# CH32L103 register map
Vendor: WCH Ltd.; File version: 1.3
Registers are 32-bit, read-write, reset 0x0 unless marked. A register's access mark holds for its fields unless they carry their own. Offsets are from the block's base; [hi:lo] are bit positions; {n}, {i} and the like mark numbered series; 'fields as' and 'values as' point back to an identical list.

## CAN — Controller area network
Base 0x40006400
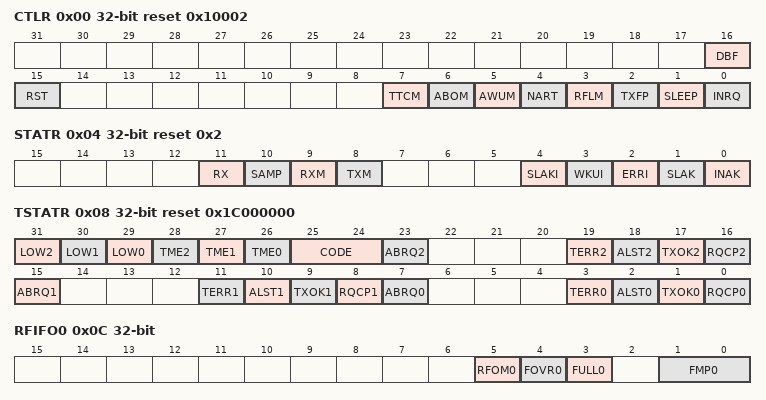
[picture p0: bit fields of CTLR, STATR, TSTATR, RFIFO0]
0x00 CTLR reset 0x10002 — CAN Master control register
  [16] DBF — Debug freeze
  [15] RST — Software master reset
  [7] TTCM — Time triggered communication mode
  [6] ABOM — Automatic bus-off management
  [5] AWUM — Automatic wakeup mode
  [4] NART — No automatic retransmission
  [3] RFLM — Receive FIFO locked mode
  [2] TXFP — Transmit FIFO priority
  [1] SLEEP — Sleep mode request bit
  [0] INRQ — Initialization request
0x04 STATR access per field reset 0x2 — CAN master status register
  [11] RX ro — Rx signal
  [10] SAMP ro — Last sample point
  [9] RXM ro — Receive mode
  [8] TXM ro — Transmit mode
  [4] SLAKI rw — Sleep acknowledge interrupt
  [3] WKUI rw — Wakeup interrupt
  [2] ERRI rw — Error interrupt
  [1] SLAK ro — Sleep acknowledge
  [0] INAK ro — Initialization acknowledge
0x08 TSTATR access per field reset 0x1C000000 — CAN transmit status register
  [31] LOW2 ro — Lowest priority flag for mailbox2
  [30] LOW1 ro — Lowest priority flag for mailbox1
  [29] LOW0 ro — Lowest priority flag for mailbox0
  [28] TME2 ro — Transmit mailbox 2 empty
  [27] TME1 ro — Transmit mailbox 1 empty
  [26] TME0 ro — Transmit mailbox 0 empty
  [25:24] CODE ro — Mailbox code
  [23] ABRQ2 rw — Abort request for mailbox 2
  [19] TERR2 rw — Transmission error of mailbox 2
  [18] ALST2 rw — Arbitration lost for mailbox 2
  [17] TXOK2 rw — Transmission OK of mailbox 2
  [16] RQCP2 rw — Request completed mailbox2
  [15] ABRQ1 rw — Abort request for mailbox 1
  [11] TERR1 rw — Transmission error of mailbox1
  [10] ALST1 rw — Arbitration lost for mailbox1
  [9] TXOK1 rw — Transmission OK of mailbox1
  [8] RQCP1 rw — Request completed mailbox1
  [7] ABRQ0 rw — Abort request for mailbox0
  [3] TERR0 rw — Transmission error of mailbox0
  [2] ALST0 rw — Arbitration lost for mailbox0
  [1] TXOK0 rw — Transmission OK of mailbox0
  [0] RQCP0 rw — Request completed mailbox0
0x0C RFIFO0 access per field — CAN receive FIFO 0 register
  [5] RFOM0 rw — Release FIFO 0 output mailbox
  [4] FOVR0 rw — FIFO 0 overrun
  [3] FULL0 rw — FIFO 0 full
  [1:0] FMP0 ro — FIFO 0 message pending
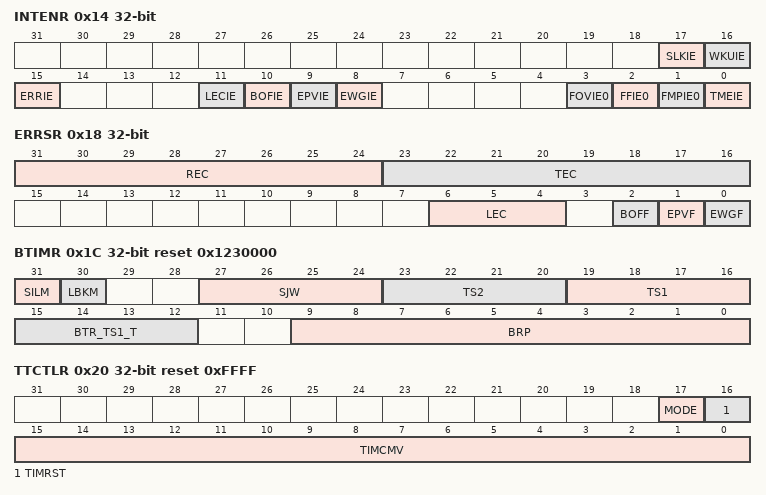
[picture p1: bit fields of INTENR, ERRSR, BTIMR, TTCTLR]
0x14 INTENR — CAN interrupt enable register
  [17] SLKIE — Sleep interrupt enable
  [16] WKUIE — Wakeup interrupt enable
  [15] ERRIE — Error interrupt enable
  [11] LECIE — Last error code interrupt enable
  [10] BOFIE — Bus-off interrupt enable
  [9] EPVIE — Error passive interrupt enable
  [8] EWGIE — Error warning interrupt enable
  [3] FOVIE0 — FIFO overrun interrupt enable
  [2] FFIE0 — FIFO full interrupt enable
  [1] FMPIE0 — FIFO message pending interrupt enable
  [0] TMEIE — Transmit mailbox empty interrupt enable
0x18 ERRSR access per field — CAN error status register
  [31:24] REC ro — Receive error counter
  [23:16] TEC ro — Least significant byte of the 9-bit transmit error counter
  [6:4] LEC rw — Last error code
  [2] BOFF ro — Bus-off flag
  [1] EPVF ro — Error passive flag
  [0] EWGF ro — Error warning flag
0x1C BTIMR reset 0x1230000 — CAN bit timing register
  [31] SILM — Silent mode (debug)
  [30] LBKM — Loop back mode (debug)
  [27:24] SJW — Resynchronization jump width
  [23:20] TS2 — Time segment 2
  [19:16] TS1 — Time segment 1
  [15:12] BTR_TS1_T — CLAS_LONG_TS1=0;TS1 is TS[3:0](4bit);CLAS_LONG_TS1=1,TS1 is TS[1:0]+BTR_TS1_T[15:12](6bit)
  [9:0] BRP — minimum time unit length setting value
0x20 TTCTLR reset 0xFFFF — CAN time trigger control register
  [17] MODE — Time-triggered mode selection
  [16] TIMRST wo — Internal counter reset control
  [15:0] TIMCMV — Internal counter count end value
0x24 TTCNT — CAN Time Trigger Count Value Register
  [15:0] TIMCNT — time-triggered count value
0x28 TERR_CNT — CAN offline recovery error counter
  [8:0] TX_ERR_CNT — Offline recovery error count values
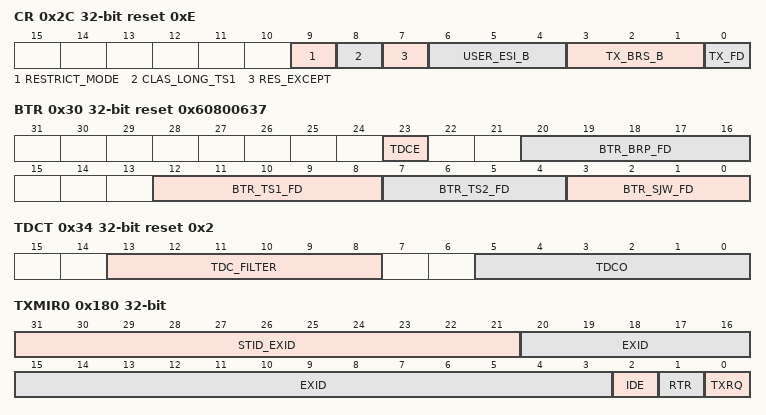
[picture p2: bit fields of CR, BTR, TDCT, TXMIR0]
0x2C CR reset 0xE — CANFD control register
  [9] RESTRICT_MODE — Mode enable
  [8] CLAS_LONG_TS1 — TS1 stage length selection
  [7] RES_EXCEPT — RES Bit exceptional enable
  [6:4] USER_ESI_B — ESI status
  [3:1] TX_BRS_B — Channel switchover enable
  [0] TX_FD — Send the FD frame enable bit
0x30 BTR reset 0x60800637 — CANFD Sequential register
  [23] TDCE — FD Frame sending delay compensation enable
  [20:16] BTR_BRP_FD — Minimum time length setting value
  [12:8] BTR_TS1_FD — Time range 1 set value
  [7:4] BTR_TS2_FD — Time range 2 set value
  [3:0] BTR_SJW_FD — Resynchronization width setting
0x34 TDCT reset 0x2 — CANFD Send delay compensation register
  [13:8] TDC_FILTER — Transmitter delay timing filtering
  [5:0] TDCO — Transmitter delay compensation offset
0x38 PSR ro — CANFD Send delay compensation value register
  [23:16] TDCV — FD Send delay compensation value
{0x3C+4i} DMA_T{i} (i=0..2) — CANFD DMA send mailbox {i} address register
  [14:0] DMA_ADDR_T{i} — Send buffer
0x48 DMA_R0 — CANFD DMA receives mailbox 0 address register
  [14:0] DMA_ADDR_R0 — Receive buffer
0x180 TXMIR0 — CAN TX mailbox identifier register
  [31:21] STID_EXID — Standard identifier
  [20:3] EXID — extended identifier
  [2] IDE — Identifier extension
  [1] RTR — Remote transmission request
  [0] TXRQ — Transmit mailbox request
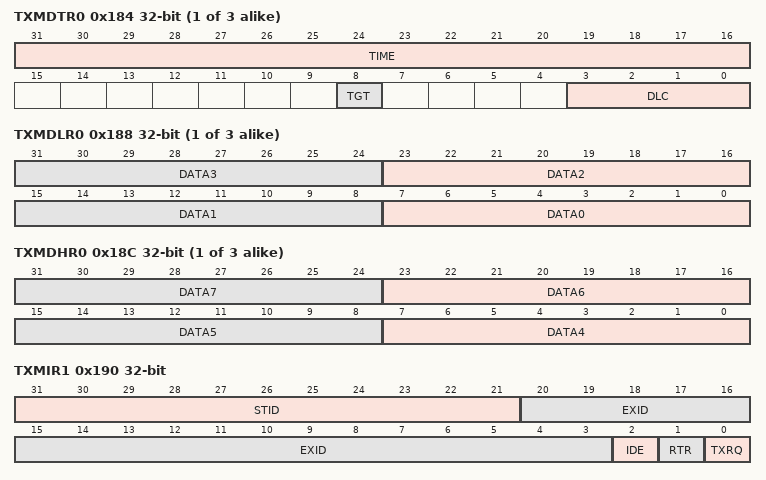
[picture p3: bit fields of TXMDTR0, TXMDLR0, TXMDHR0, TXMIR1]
{0x184+0x10*i} TXMDTR{i} (i=0..2) — CAN mailbox data length control and time stamp register
  [31:16] TIME — Message time stamp
  [8] TGT — Transmit global time
  [3:0] DLC — Data length code
{0x188+0x10*i} TXMDLR{i} (i=0..2) — CAN mailbox data low register
  [8n+7:8n] DATA{n} (n=0..3) — Data byte {n}
{0x18C+0x10*i} TXMDHR{i} (i=0..2) — CAN mailbox data high register
  [8n-25:8n-32] DATA{n} (n=4..7) — Data byte {n}
0x190 TXMIR1 — CAN TX mailbox identifier register
  [31:21] STID — Standard identifier
  [20:3] EXID — extended identifier
  [2] IDE — Identifier extension
  [1] RTR — Remote transmission request
  [0] TXRQ — Transmit mailbox request
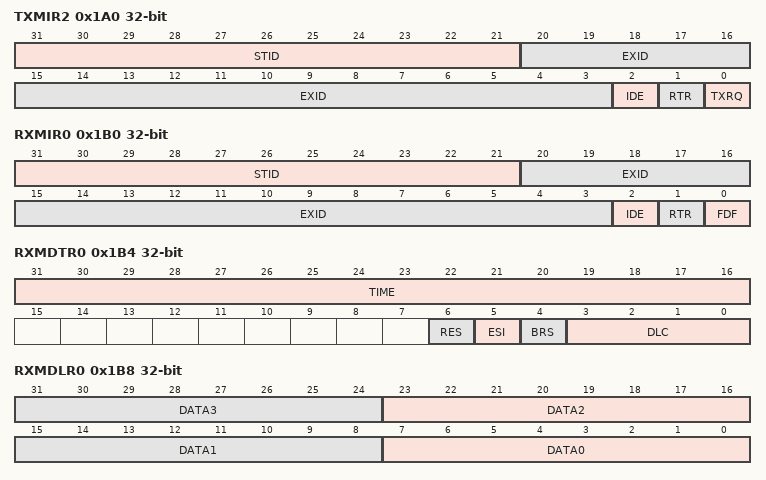
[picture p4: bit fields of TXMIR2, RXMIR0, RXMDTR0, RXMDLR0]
0x1A0 TXMIR2 — CAN TX mailbox identifier register
  fields as TXMIR1
0x1B0 RXMIR0 ro — CAN receive FIFO mailbox identifier register
  [31:21] STID — Standard identifier
  [20:3] EXID — extended identifier
  [2] IDE — Identifier extension
  [1] RTR — Remote transmission request
  [0] FDF — Receive FD frame indication flag
0x1B4 RXMDTR0 ro — CAN receive FIFO mailbox data length control and time stamp register
  [31:16] TIME — Message time stamp
  [6] RES — RES bit of the received frame
  [5] ESI — ESI bit of the received frame
  [4] BRS — BRS bit of the received frame
  [3:0] DLC — Data length code
0x1B8 RXMDLR0 ro — CAN receive FIFO mailbox data low register
  [8n+7:8n] DATA{n} (n=0..3) — Data Byte {n}
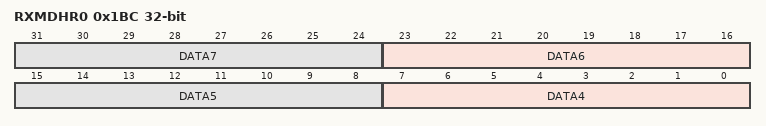
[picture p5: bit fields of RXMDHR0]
0x1BC RXMDHR0 ro — CAN receive FIFO mailbox data high register
  [8n-25:8n-32] DATA{n} (n=4..7)
